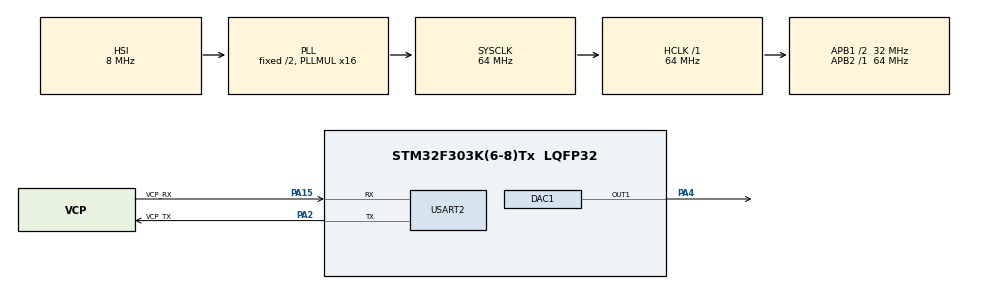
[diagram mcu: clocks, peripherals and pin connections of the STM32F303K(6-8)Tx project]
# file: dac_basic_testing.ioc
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DAC1.DAC_OutputBuffer=DAC_OUTPUTBUFFER_DISABLE
Mcu.Family=STM32F3
Mcu.Name=STM32F303K(6-8)Tx
Mcu.Package=LQFP32
NVIC.PriorityGroup=NVIC_PRIORITYGROUP_4
PA13.GPIO_Label=SWDIO
PA13.Mode=Serial_Wire
PA13.Signal=SYS_JTMS-SWDIO
PA14.GPIO_Label=SWCLK
PA14.Mode=Serial_Wire
PA14.Signal=SYS_JTCK-SWCLK
PA15.GPIO_Label=VCP_RX
PA15.Mode=Asynchronous
PA15.Signal=USART2_RX
PA2.GPIO_Label=VCP_TX
PA2.Mode=Asynchronous
PA2.Signal=USART2_TX
PA4.Signal=COMP_DAC11_group
PF0\ /\ OSC_IN.GPIO_Label=MCO
PF0\ /\ OSC_IN.Mode=HSE-External-Clock-Source
PF0\ /\ OSC_IN.Signal=RCC_OSC_IN
ProjectManager.HeapSize=0x200
ProjectManager.StackSize=0x400
ProjectManager.TargetToolchain=STM32CubeIDE
RCC.AHBFreq_Value=64000000
RCC.APB1CLKDivider=RCC_HCLK_DIV2
RCC.APB1Freq_Value=32000000
RCC.APB1TimFreq_Value=64000000
RCC.APB2Freq_Value=64000000
RCC.APB2TimFreq_Value=64000000
RCC.CortexFreq_Value=64000000
RCC.HCLKFreq_Value=64000000
RCC.HSE_VALUE=8000000
RCC.HSI_VALUE=8000000
RCC.PLLMUL=RCC_PLL_MUL16
RCC.SYSCLKFreq_VALUE=64000000
RCC.SYSCLKSourceVirtual=RCC_SYSCLKSOURCE_PLLCLK
SH.COMP_DAC11_group.0=DAC1_OUT1,DAC_OUT1
USART2.VirtualMode-Asynchronous=VM_ASYNC
board=NUCLEO-F303K8

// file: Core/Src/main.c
/* USER CODE BEGIN Header */
/**
  ******************************************************************************
  * @file           : main.c
  * @brief          : Main program body
  ******************************************************************************
  * @attention
  *
  * Copyright (c) 2024 STMicroelectronics.
  * All rights reserved.
  *
  * This software is licensed under terms that can be found in the LICENSE file
  * in the root directory of this software component.
  * If no LICENSE file comes with this software, it is provided AS-IS.
  *
  ******************************************************************************
  */

//- DAC1_OUT1 / pin 10 / PA4 (A3): buffered => TX_AMP_RAW
//- DAC2_OUT1 / pin 12 / PA6 (A5): unbuffered => AUDIO

/* USER CODE END Header */
#include "main.h"

DAC_HandleTypeDef hdac1;

UART_HandleTypeDef huart2;

void SystemClock_Config(void);
static void MX_GPIO_Init(void);
static void MX_USART2_UART_Init(void);
static void MX_DAC1_Init(void);

/* USER CODE BEGIN 0 */

#define WAVE_BUFFER_CAPACITY 4096	//way bigger than needed

uint16_t waveAmplitude;//DAC counts ranging from [0,4095]
uint16_t waveFrequency;//[Hz]
uint32_t waveSize;//[points]
uint16_t waveBuffer[WAVE_BUFFER_CAPACITY];

int GenerateWaveToTransmit(double sampleRate, double frequency, double amplitude, double center)
{
    double sampleTime = 1.0 / sampleRate;//[sec/sample]
    uint32_t samplesPerCycle = (uint32_t)round(sampleRate / frequency);

    if (samplesPerCycle >= WAVE_BUFFER_CAPACITY) return 2;

    for (uint32_t i = 0; i < samplesPerCycle; i++)
    {
        double timeS = (i) * sampleTime;
        double waveValue = amplitude * sin(2 * M_PI * frequency * timeS) + center;
        uint16_t waveValueInt = (uint16_t)round(waveValue);
        if (waveValueInt < 0) return -1;//waveValue = 0;//TODO: test and see if I can remove this
		if (waveValueInt > 4095) return 1;//waveValue = 4095;
        waveBuffer[i] = waveValueInt;
    }

    waveAmplitude = (uint16_t) amplitude;
    waveFrequency = (uint16_t) frequency;
    waveSize = samplesPerCycle;

    return 0;
}

/* USER CODE END 0 */

int main(void)
{

  /* MCU Configuration--------------------------------------------------------*/

  /* Reset of all peripherals, Initializes the Flash interface and the Systick. */
  HAL_Init();

  /* Configure the system clock */
  SystemClock_Config();

  /* Initialize all configured peripherals */
  MX_GPIO_Init();
  MX_USART2_UART_Init();
  MX_DAC1_Init();
  /* USER CODE BEGIN 2 */

  double sampleRate = 500000;//samples/sec
  double frequency = 10000;
  double amplitude = 2047.5;
  double center = 2047.5;
  int result = GenerateWaveToTransmit(sampleRate, frequency, amplitude, center);
  if (result != 0) {
	  while(1) {
		  //todo: error code / light / etc
		  asm volatile("nop");
	  }
  }

  //hdac1
  HAL_DAC_Start(&hdac1, DAC_CHANNEL_1);

  //float dacARef = 3.31f;
  //float dacValueVolts = 0.1f;
  //uint16_t dacValue = (uint16_t)roundf(dacValueVolts * 4095 / dacARef);
  //HAL_DAC_SetValue(&hdac1, DAC_CHANNEL_1, DAC_ALIGN_12B_R, (uint32_t) dacValue);

  /* USER CODE END 2 */

  /* Infinite loop */
  /* USER CODE BEGIN WHILE */
  uint16_t i = 0;
  //uint32_t timeOffset = 0;
  //uint16_t j = 0;
  uint16_t value;
  while (1)
  {
	  //value = waveBuffer[i++];
	  //HAL_DAC_SetValue(&hdac1, DAC_CHANNEL_1, DAC_ALIGN_12B_R, (uint32_t) value);
	  //if (i >= waveSize) i = 0;

	  //HAL_Delay(1.0f/sampleRate * 1000 - timeOffset);
	  /*for (j=0; j<2; j++)*/
	  //asm volatile("nop");

    /* USER CODE END WHILE */

  }
}

void SystemClock_Config(void)
{
  RCC_OscInitTypeDef RCC_OscInitStruct = {0};
  RCC_ClkInitTypeDef RCC_ClkInitStruct = {0};

  /** Initializes the RCC Oscillators according to the specified parameters
  * in the RCC_OscInitTypeDef structure.
  */
  RCC_OscInitStruct.OscillatorType = RCC_OSCILLATORTYPE_HSI;
  RCC_OscInitStruct.HSIState = RCC_HSI_ON;
  RCC_OscInitStruct.HSICalibrationValue = RCC_HSICALIBRATION_DEFAULT;
  RCC_OscInitStruct.PLL.PLLState = RCC_PLL_ON;
  RCC_OscInitStruct.PLL.PLLSource = RCC_PLLSOURCE_HSI;
  RCC_OscInitStruct.PLL.PLLMUL = RCC_PLL_MUL16;
  if (HAL_RCC_OscConfig(&RCC_OscInitStruct) != HAL_OK)
  {
    Error_Handler();
  }

  /** Initializes the CPU, AHB and APB buses clocks
  */
  RCC_ClkInitStruct.ClockType = RCC_CLOCKTYPE_HCLK|RCC_CLOCKTYPE_SYSCLK
                              |RCC_CLOCKTYPE_PCLK1|RCC_CLOCKTYPE_PCLK2;
  RCC_ClkInitStruct.SYSCLKSource = RCC_SYSCLKSOURCE_PLLCLK;
  RCC_ClkInitStruct.AHBCLKDivider = RCC_SYSCLK_DIV1;
  RCC_ClkInitStruct.APB1CLKDivider = RCC_HCLK_DIV2;
  RCC_ClkInitStruct.APB2CLKDivider = RCC_HCLK_DIV1;

  if (HAL_RCC_ClockConfig(&RCC_ClkInitStruct, FLASH_LATENCY_2) != HAL_OK)
  {
    Error_Handler();
  }
}

static void MX_DAC1_Init(void)
{

  DAC_ChannelConfTypeDef sConfig = {0};

  /** DAC Initialization
  */
  hdac1.Instance = DAC1;
  if (HAL_DAC_Init(&hdac1) != HAL_OK)
  {
    Error_Handler();
  }

  /** DAC channel OUT1 config
  */
  sConfig.DAC_Trigger = DAC_TRIGGER_NONE;
  sConfig.DAC_OutputBuffer = DAC_OUTPUTBUFFER_DISABLE;
  if (HAL_DAC_ConfigChannel(&hdac1, &sConfig, DAC_CHANNEL_1) != HAL_OK)
  {
    Error_Handler();
  }

}

static void MX_USART2_UART_Init(void)
{

  huart2.Instance = USART2;
  huart2.Init.BaudRate = 38400;
  huart2.Init.WordLength = UART_WORDLENGTH_8B;
  huart2.Init.StopBits = UART_STOPBITS_1;
  huart2.Init.Parity = UART_PARITY_NONE;
  huart2.Init.Mode = UART_MODE_TX_RX;
  huart2.Init.HwFlowCtl = UART_HWCONTROL_NONE;
  huart2.Init.OverSampling = UART_OVERSAMPLING_16;
  huart2.Init.OneBitSampling = UART_ONE_BIT_SAMPLE_DISABLE;
  huart2.AdvancedInit.AdvFeatureInit = UART_ADVFEATURE_NO_INIT;
  if (HAL_UART_Init(&huart2) != HAL_OK)
  {
    Error_Handler();
  }

}

static void MX_GPIO_Init(void)
{

  /* GPIO Ports Clock Enable */
  __HAL_RCC_GPIOF_CLK_ENABLE();
  __HAL_RCC_GPIOA_CLK_ENABLE();

}

void Error_Handler(void)
{
  __disable_irq();
  while (1)
  {
  }
}
